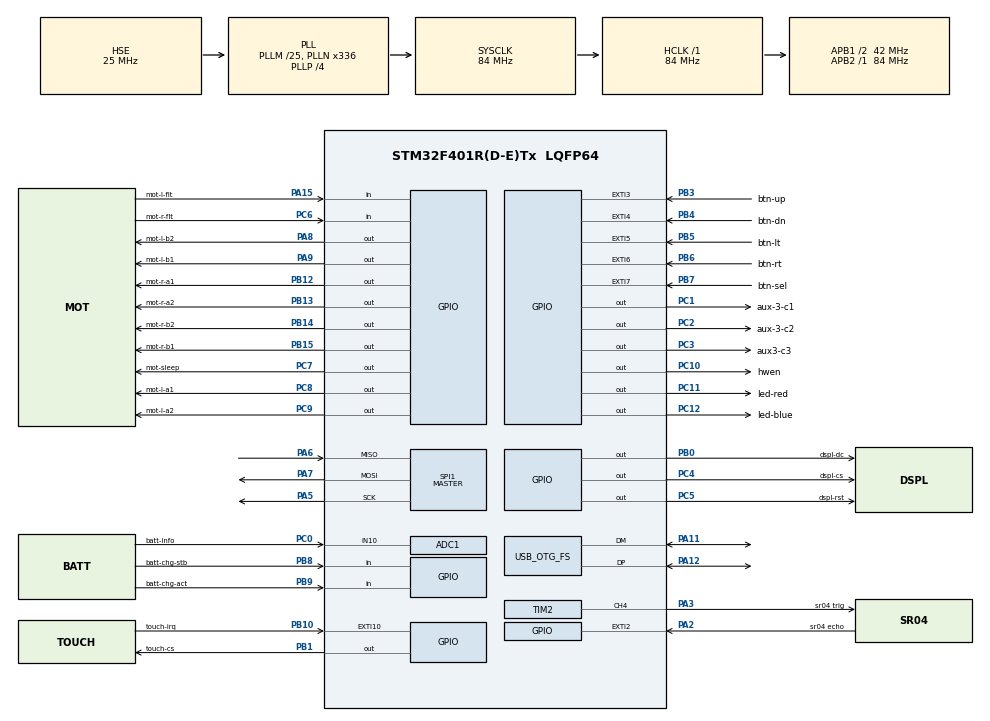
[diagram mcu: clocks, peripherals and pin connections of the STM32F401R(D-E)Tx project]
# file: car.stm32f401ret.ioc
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ADC1.Channel-0\#ChannelRegularConversion=ADC_CHANNEL_10
ADC1.NbrOfConversionFlag=1
ADC1.Rank-0\#ChannelRegularConversion=1
ADC1.SamplingTime-0\#ChannelRegularConversion=ADC_SAMPLETIME_3CYCLES
ADC1.master=1
Dma.Request0=SPI1_TX
Dma.SPI1_TX.0.Direction=DMA_MEMORY_TO_PERIPH
Dma.SPI1_TX.0.FIFOMode=DMA_FIFOMODE_DISABLE
Dma.SPI1_TX.0.Instance=DMA2_Stream3
Dma.SPI1_TX.0.MemDataAlignment=DMA_MDATAALIGN_BYTE
Dma.SPI1_TX.0.MemInc=DMA_MINC_ENABLE
Dma.SPI1_TX.0.Mode=DMA_NORMAL
Dma.SPI1_TX.0.PeriphDataAlignment=DMA_PDATAALIGN_BYTE
Dma.SPI1_TX.0.PeriphInc=DMA_PINC_DISABLE
Dma.SPI1_TX.0.Priority=DMA_PRIORITY_LOW
Mcu.Family=STM32F4
Mcu.Name=STM32F401R(D-E)Tx
Mcu.Package=LQFP64
NVIC.DMA2_Stream3_IRQn=true\:0\:0\:false\:false\:true\:false\:true\:true
NVIC.EXTI2_IRQn=true\:0\:0\:false\:false\:true\:true\:true\:true
NVIC.EXTI3_IRQn=true\:0\:0\:false\:false\:true\:true\:true\:true
NVIC.EXTI4_IRQn=true\:0\:0\:false\:false\:true\:true\:true\:true
NVIC.EXTI9_5_IRQn=true\:0\:0\:false\:false\:true\:true\:true\:true
NVIC.OTG_FS_IRQn=true\:0\:0\:false\:false\:true\:false\:true\:true
NVIC.PriorityGroup=NVIC_PRIORITYGROUP_4
NVIC.TIM1_UP_TIM10_IRQn=true\:0\:0\:false\:false\:true\:true\:true\:true
PA11.Mode=Device_Only
PA11.Signal=USB_OTG_FS_DM
PA12.Mode=Device_Only
PA12.Signal=USB_OTG_FS_DP
PA15.GPIO_Label=mot-l-flt
PA15.GPIO_PuPd=GPIO_PULLUP
PA15.Signal=GPIO_Input
PA2.GPIO_Label=sr04 echo
PA2.GPIO_ModeDefaultEXTI=GPIO_MODE_IT_RISING_FALLING
PA2.GPIO_PuPd=GPIO_PULLDOWN
PA2.Signal=GPXTI2
PA3.GPIO_Label=sr04 trig
PA3.GPIO_Speed=GPIO_SPEED_FREQ_HIGH
PA3.Signal=S_TIM2_CH4
PA5.Mode=Full_Duplex_Master
PA5.Signal=SPI1_SCK
PA6.Mode=Full_Duplex_Master
PA6.Signal=SPI1_MISO
PA7.Mode=Full_Duplex_Master
PA7.Signal=SPI1_MOSI
PA8.GPIO_Label=mot-l-b2
PA8.Signal=GPIO_Output
PA9.GPIO_Label=mot-l-b1
PA9.Signal=GPIO_Output
PB0.GPIO_Label=dspl-dc
PB0.GPIO_Speed=GPIO_SPEED_FREQ_HIGH
PB0.PinState=GPIO_PIN_RESET
PB0.Signal=GPIO_Output
PB1.GPIO_Label=touch-cs
PB1.GPIO_Speed=GPIO_SPEED_FREQ_HIGH
PB1.PinState=GPIO_PIN_SET
PB1.Signal=GPIO_Output
PB10.GPIO_Label=touch-irq
PB10.Signal=GPXTI10
PB12.GPIO_Label=mot-r-a1
PB12.Signal=GPIO_Output
PB13.GPIO_Label=mot-r-a2
PB13.Signal=GPIO_Output
PB14.GPIO_Label=mot-r-b2
PB14.Signal=GPIO_Output
PB15.GPIO_Label=mot-r-b1
PB15.Signal=GPIO_Output
PB3.GPIO_Label=btn-up
PB3.GPIO_ModeDefaultEXTI=GPIO_MODE_IT_FALLING
PB3.GPIO_PuPd=GPIO_PULLUP
PB3.Signal=GPXTI3
PB4.GPIO_Label=btn-dn
PB4.GPIO_ModeDefaultEXTI=GPIO_MODE_IT_FALLING
PB4.GPIO_PuPd=GPIO_PULLUP
PB4.Signal=GPXTI4
PB5.GPIO_Label=btn-lt
PB5.GPIO_ModeDefaultEXTI=GPIO_MODE_IT_FALLING
PB5.GPIO_PuPd=GPIO_PULLUP
PB5.Signal=GPXTI5
PB6.GPIO_Label=btn-rt
PB6.GPIO_ModeDefaultEXTI=GPIO_MODE_IT_FALLING
PB6.GPIO_PuPd=GPIO_PULLUP
PB6.Signal=GPXTI6
PB7.GPIO_Label=btn-sel
PB7.GPIO_ModeDefaultEXTI=GPIO_MODE_IT_FALLING
PB7.GPIO_PuPd=GPIO_PULLUP
PB7.Signal=GPXTI7
PB8.GPIO_Label=batt-chg-stb
PB8.GPIO_PuPd=GPIO_PULLUP
PB8.Signal=GPIO_Input
PB9.GPIO_Label=batt-chg-act
PB9.GPIO_PuPd=GPIO_PULLUP
PB9.Signal=GPIO_Input
PC0.GPIO_Label=batt-info
PC0.Signal=ADCx_IN10
PC1.GPIO_Label=aux-3-c1
PC1.Signal=GPIO_Output
PC10.GPIO_Label=hwen
PC10.PinState=GPIO_PIN_SET
PC10.Signal=GPIO_Output
PC11.GPIO_Label=led-red
PC11.Signal=GPIO_Output
PC12.GPIO_Label=led-blue
PC12.Signal=GPIO_Output
PC14-OSC32_IN.Mode=LSE-External-Oscillator
PC14-OSC32_IN.Signal=RCC_OSC32_IN
PC15-OSC32_OUT.Mode=LSE-External-Oscillator
PC15-OSC32_OUT.Signal=RCC_OSC32_OUT
PC2.GPIO_Label=aux-3-c2
PC2.Signal=GPIO_Output
PC3.GPIO_Label=aux3-c3
PC3.Signal=GPIO_Output
PC4.GPIO_Label=dspl-cs
PC4.GPIO_Speed=GPIO_SPEED_FREQ_HIGH
PC4.PinState=GPIO_PIN_SET
PC4.Signal=GPIO_Output
PC5.GPIO_Label=dspl-rst
PC5.Signal=GPIO_Output
PC6.GPIO_Label=mot-r-flt
PC6.GPIO_PuPd=GPIO_PULLUP
PC6.Signal=GPIO_Input
PC7.GPIO_Label=mot-sleep
PC7.GPIO_Speed=GPIO_SPEED_FREQ_LOW
PC7.PinState=GPIO_PIN_SET
PC7.Signal=GPIO_Output
PC8.GPIO_Label=mot-l-a1
PC8.Signal=GPIO_Output
PC9.GPIO_Label=mot-l-a2
PC9.Signal=GPIO_Output
PH0\ -\ OSC_IN.Mode=HSE-External-Oscillator
PH0\ -\ OSC_IN.Signal=RCC_OSC_IN
PH1\ -\ OSC_OUT.Mode=HSE-External-Oscillator
PH1\ -\ OSC_OUT.Signal=RCC_OSC_OUT
ProjectManager.HeapSize=0x200
ProjectManager.StackSize=0x400
ProjectManager.TargetToolchain=Makefile
RCC.48MHZClocksFreq_Value=48000000
RCC.AHBFreq_Value=84000000
RCC.APB1CLKDivider=RCC_HCLK_DIV2
RCC.APB1Freq_Value=42000000
RCC.APB1TimFreq_Value=84000000
RCC.APB2Freq_Value=84000000
RCC.APB2TimFreq_Value=84000000
RCC.CortexFreq_Value=84000000
RCC.HCLKFreq_Value=84000000
RCC.HSE_VALUE=25000000
RCC.HSI_VALUE=16000000
RCC.PLLM=25
RCC.PLLN=336
RCC.PLLP=RCC_PLLP_DIV4
RCC.PLLQ=7
RCC.RCC_RTC_Clock_Source=RCC_RTCCLKSOURCE_LSE
RCC.RCC_RTC_Clock_SourceVirtual=RCC_RTCCLKSOURCE_LSE
RCC.SYSCLKFreq_VALUE=84000000
RCC.SYSCLKSource=RCC_SYSCLKSOURCE_PLLCLK
RCC.VCOOutputFreq_Value=336000000
SH.ADCx_IN10.0=ADC1_IN10,IN10
SH.S_TIM2_CH4.0=TIM2_CH4,PWM Generation4 CH4
SPI1.BaudRatePrescaler=SPI_BAUDRATEPRESCALER_2
SPI1.Direction=SPI_DIRECTION_2LINES
SPI1.Mode=SPI_MODE_MASTER
SPI1.VirtualType=VM_MASTER
TIM1.AutoReloadPreload=TIM_AUTORELOAD_PRELOAD_DISABLE
TIM1.Period=99
TIM1.Prescaler=839
TIM2.Channel-PWM\ Generation4\ CH4=TIM_CHANNEL_4
TIM2.Period=59999
TIM2.Prescaler=83
TIM2.Pulse-PWM\ Generation4\ CH4=9
USB_DEVICE.CLASS_NAME_FS=CDC
USB_DEVICE.MANUFACTURER_STRING=cliff
USB_DEVICE.PRODUCT_STRING_CDC_FS=car Virtual ComPort
USB_DEVICE.VirtualMode=Cdc
USB_DEVICE.VirtualMode-CDC_FS=Cdc
USB_DEVICE.VirtualModeFS=Cdc_FS
USB_OTG_FS.VirtualMode=Device_Only
VP_RTC_VS_RTC_Activate.Mode=RTC_Enabled
VP_TIM1_VS_ClockSourceINT.Mode=Internal
VP_TIM2_VS_ClockSourceINT.Mode=Internal
VP_USB_DEVICE_VS_USB_DEVICE_CDC_FS.Mode=CDC_FS
board=custom

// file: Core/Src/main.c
/* USER CODE BEGIN Header */
/**
  ******************************************************************************
  * @file           : main.c
  * @brief          : Main program body
  ******************************************************************************
  * @attention
  *
  * Copyright (c) 2025 STMicroelectronics.
  * All rights reserved.
  *
  * This software is licensed under terms that can be found in the LICENSE file
  * in the root directory of this software component.
  * If no LICENSE file comes with this software, it is provided AS-IS.
  *
  ******************************************************************************
  */
/* USER CODE END Header */
#include "main.h"
#include "usb_device.h"

/* USER CODE BEGIN Includes */
#include "../../source/sys/proc.h"

/* USER CODE END Includes */

ADC_HandleTypeDef hadc1;

RTC_HandleTypeDef hrtc;

SPI_HandleTypeDef hspi1;
DMA_HandleTypeDef hdma_spi1_tx;

TIM_HandleTypeDef htim1;
TIM_HandleTypeDef htim2;

void SystemClock_Config(void);
static void MX_GPIO_Init(void);
static void MX_DMA_Init(void);
static void MX_RTC_Init(void);
static void MX_SPI1_Init(void);
static void MX_ADC1_Init(void);
static void MX_TIM1_Init(void);
static void MX_TIM2_Init(void);

int main(void)
{

  /* MCU Configuration--------------------------------------------------------*/

  /* Reset of all peripherals, Initializes the Flash interface and the Systick. */
  HAL_Init();

  /* Configure the system clock */
  SystemClock_Config();

  /* Initialize all configured peripherals */
  MX_GPIO_Init();
  MX_DMA_Init();
  MX_RTC_Init();
  MX_SPI1_Init();
  MX_USB_DEVICE_Init();
  MX_ADC1_Init();
  MX_TIM1_Init();
  MX_TIM2_Init();
  /* USER CODE BEGIN 2 */

    init();

  /* USER CODE END 2 */

  /* Infinite loop */
  /* USER CODE BEGIN WHILE */
  while (1)
  {
    HAL_GPIO_TogglePin(GPIOC, GPIO_PIN_13);
    HAL_Delay(1000);
    /* USER CODE END WHILE */

  }
}

void SystemClock_Config(void)
{
  RCC_OscInitTypeDef RCC_OscInitStruct = {0};
  RCC_ClkInitTypeDef RCC_ClkInitStruct = {0};

  /** Configure the main internal regulator output voltage
  */
  __HAL_RCC_PWR_CLK_ENABLE();
  __HAL_PWR_VOLTAGESCALING_CONFIG(PWR_REGULATOR_VOLTAGE_SCALE2);

  /** Initializes the RCC Oscillators according to the specified parameters
  * in the RCC_OscInitTypeDef structure.
  */
  RCC_OscInitStruct.OscillatorType = RCC_OSCILLATORTYPE_HSE|RCC_OSCILLATORTYPE_LSE;
  RCC_OscInitStruct.HSEState = RCC_HSE_ON;
  RCC_OscInitStruct.LSEState = RCC_LSE_ON;
  RCC_OscInitStruct.PLL.PLLState = RCC_PLL_ON;
  RCC_OscInitStruct.PLL.PLLSource = RCC_PLLSOURCE_HSE;
  RCC_OscInitStruct.PLL.PLLM = 25;
  RCC_OscInitStruct.PLL.PLLN = 336;
  RCC_OscInitStruct.PLL.PLLP = RCC_PLLP_DIV4;
  RCC_OscInitStruct.PLL.PLLQ = 7;
  if (HAL_RCC_OscConfig(&RCC_OscInitStruct) != HAL_OK)
  {
    Error_Handler();
  }

  /** Initializes the CPU, AHB and APB buses clocks
  */
  RCC_ClkInitStruct.ClockType = RCC_CLOCKTYPE_HCLK|RCC_CLOCKTYPE_SYSCLK
                              |RCC_CLOCKTYPE_PCLK1|RCC_CLOCKTYPE_PCLK2;
  RCC_ClkInitStruct.SYSCLKSource = RCC_SYSCLKSOURCE_PLLCLK;
  RCC_ClkInitStruct.AHBCLKDivider = RCC_SYSCLK_DIV1;
  RCC_ClkInitStruct.APB1CLKDivider = RCC_HCLK_DIV2;
  RCC_ClkInitStruct.APB2CLKDivider = RCC_HCLK_DIV1;

  if (HAL_RCC_ClockConfig(&RCC_ClkInitStruct, FLASH_LATENCY_2) != HAL_OK)
  {
    Error_Handler();
  }
}

static void MX_ADC1_Init(void)
{

  ADC_ChannelConfTypeDef sConfig = {0};

  /** Configure the global features of the ADC (Clock, Resolution, Data Alignment and number of conversion)
  */
  hadc1.Instance = ADC1;
  hadc1.Init.ClockPrescaler = ADC_CLOCK_SYNC_PCLK_DIV4;
  hadc1.Init.Resolution = ADC_RESOLUTION_12B;
  hadc1.Init.ScanConvMode = DISABLE;
  hadc1.Init.ContinuousConvMode = DISABLE;
  hadc1.Init.DiscontinuousConvMode = DISABLE;
  hadc1.Init.ExternalTrigConvEdge = ADC_EXTERNALTRIGCONVEDGE_NONE;
  hadc1.Init.ExternalTrigConv = ADC_SOFTWARE_START;
  hadc1.Init.DataAlign = ADC_DATAALIGN_RIGHT;
  hadc1.Init.NbrOfConversion = 1;
  hadc1.Init.DMAContinuousRequests = DISABLE;
  hadc1.Init.EOCSelection = ADC_EOC_SINGLE_CONV;
  if (HAL_ADC_Init(&hadc1) != HAL_OK)
  {
    Error_Handler();
  }

  /** Configure for the selected ADC regular channel its corresponding rank in the sequencer and its sample time.
  */
  sConfig.Channel = ADC_CHANNEL_10;
  sConfig.Rank = 1;
  sConfig.SamplingTime = ADC_SAMPLETIME_3CYCLES;
  if (HAL_ADC_ConfigChannel(&hadc1, &sConfig) != HAL_OK)
  {
    Error_Handler();
  }

}

static void MX_RTC_Init(void)
{

  /** Initialize RTC Only
  */
  hrtc.Instance = RTC;
  hrtc.Init.HourFormat = RTC_HOURFORMAT_24;
  hrtc.Init.AsynchPrediv = 127;
  hrtc.Init.SynchPrediv = 255;
  hrtc.Init.OutPut = RTC_OUTPUT_DISABLE;
  hrtc.Init.OutPutPolarity = RTC_OUTPUT_POLARITY_HIGH;
  hrtc.Init.OutPutType = RTC_OUTPUT_TYPE_OPENDRAIN;
  if (HAL_RTC_Init(&hrtc) != HAL_OK)
  {
    Error_Handler();
  }

}

static void MX_SPI1_Init(void)
{

  /* SPI1 parameter configuration*/
  hspi1.Instance = SPI1;
  hspi1.Init.Mode = SPI_MODE_MASTER;
  hspi1.Init.Direction = SPI_DIRECTION_2LINES;
  hspi1.Init.DataSize = SPI_DATASIZE_8BIT;
  hspi1.Init.CLKPolarity = SPI_POLARITY_LOW;
  hspi1.Init.CLKPhase = SPI_PHASE_1EDGE;
  hspi1.Init.NSS = SPI_NSS_SOFT;
  hspi1.Init.BaudRatePrescaler = SPI_BAUDRATEPRESCALER_2;
  hspi1.Init.FirstBit = SPI_FIRSTBIT_MSB;
  hspi1.Init.TIMode = SPI_TIMODE_DISABLE;
  hspi1.Init.CRCCalculation = SPI_CRCCALCULATION_DISABLE;
  hspi1.Init.CRCPolynomial = 10;
  if (HAL_SPI_Init(&hspi1) != HAL_OK)
  {
    Error_Handler();
  }

}

static void MX_TIM1_Init(void)
{

  TIM_ClockConfigTypeDef sClockSourceConfig = {0};
  TIM_MasterConfigTypeDef sMasterConfig = {0};

  htim1.Instance = TIM1;
  htim1.Init.Prescaler = 839;
  htim1.Init.CounterMode = TIM_COUNTERMODE_UP;
  htim1.Init.Period = 99;
  htim1.Init.ClockDivision = TIM_CLOCKDIVISION_DIV1;
  htim1.Init.RepetitionCounter = 0;
  htim1.Init.AutoReloadPreload = TIM_AUTORELOAD_PRELOAD_DISABLE;
  if (HAL_TIM_Base_Init(&htim1) != HAL_OK)
  {
    Error_Handler();
  }
  sClockSourceConfig.ClockSource = TIM_CLOCKSOURCE_INTERNAL;
  if (HAL_TIM_ConfigClockSource(&htim1, &sClockSourceConfig) != HAL_OK)
  {
    Error_Handler();
  }
  sMasterConfig.MasterOutputTrigger = TIM_TRGO_RESET;
  sMasterConfig.MasterSlaveMode = TIM_MASTERSLAVEMODE_DISABLE;
  if (HAL_TIMEx_MasterConfigSynchronization(&htim1, &sMasterConfig) != HAL_OK)
  {
    Error_Handler();
  }

}

static void MX_TIM2_Init(void)
{

  TIM_ClockConfigTypeDef sClockSourceConfig = {0};
  TIM_MasterConfigTypeDef sMasterConfig = {0};
  TIM_OC_InitTypeDef sConfigOC = {0};

  htim2.Instance = TIM2;
  htim2.Init.Prescaler = 83;
  htim2.Init.CounterMode = TIM_COUNTERMODE_UP;
  htim2.Init.Period = 59999;
  htim2.Init.ClockDivision = TIM_CLOCKDIVISION_DIV1;
  htim2.Init.AutoReloadPreload = TIM_AUTORELOAD_PRELOAD_DISABLE;
  if (HAL_TIM_Base_Init(&htim2) != HAL_OK)
  {
    Error_Handler();
  }
  sClockSourceConfig.ClockSource = TIM_CLOCKSOURCE_INTERNAL;
  if (HAL_TIM_ConfigClockSource(&htim2, &sClockSourceConfig) != HAL_OK)
  {
    Error_Handler();
  }
  if (HAL_TIM_PWM_Init(&htim2) != HAL_OK)
  {
    Error_Handler();
  }
  sMasterConfig.MasterOutputTrigger = TIM_TRGO_RESET;
  sMasterConfig.MasterSlaveMode = TIM_MASTERSLAVEMODE_DISABLE;
  if (HAL_TIMEx_MasterConfigSynchronization(&htim2, &sMasterConfig) != HAL_OK)
  {
    Error_Handler();
  }
  sConfigOC.OCMode = TIM_OCMODE_PWM1;
  sConfigOC.Pulse = 9;
  sConfigOC.OCPolarity = TIM_OCPOLARITY_HIGH;
  sConfigOC.OCFastMode = TIM_OCFAST_DISABLE;
  if (HAL_TIM_PWM_ConfigChannel(&htim2, &sConfigOC, TIM_CHANNEL_4) != HAL_OK)
  {
    Error_Handler();
  }
  HAL_TIM_MspPostInit(&htim2);

}

static void MX_DMA_Init(void)
{

  /* DMA controller clock enable */
  __HAL_RCC_DMA2_CLK_ENABLE();

  /* DMA interrupt init */
  /* DMA2_Stream3_IRQn interrupt configuration */
  HAL_NVIC_SetPriority(DMA2_Stream3_IRQn, 0, 0);
  HAL_NVIC_EnableIRQ(DMA2_Stream3_IRQn);

}

static void MX_GPIO_Init(void)
{
  GPIO_InitTypeDef GPIO_InitStruct = {0};

  /* GPIO Ports Clock Enable */
  __HAL_RCC_GPIOC_CLK_ENABLE();
  __HAL_RCC_GPIOH_CLK_ENABLE();
  __HAL_RCC_GPIOA_CLK_ENABLE();
  __HAL_RCC_GPIOB_CLK_ENABLE();

  /*Configure GPIO pin Output Level */
  HAL_GPIO_WritePin(GPIOC, aux_3_c1_Pin|aux_3_c2_Pin|aux3_c3_Pin|dspl_rst_Pin
                          |mot_l_a1_Pin|mot_l_a2_Pin|led_red_Pin|led_blue_Pin, GPIO_PIN_RESET);

  /*Configure GPIO pin Output Level */
  HAL_GPIO_WritePin(GPIOC, dspl_cs_Pin|mot_sleep_Pin|hwen_Pin, GPIO_PIN_SET);

  /*Configure GPIO pin Output Level */
  HAL_GPIO_WritePin(GPIOB, dspl_dc_Pin|mot_r_a1_Pin|mot_r_a2_Pin|mot_r_b2_Pin
                          |mot_r_b1_Pin, GPIO_PIN_RESET);

  /*Configure GPIO pin Output Level */
  HAL_GPIO_WritePin(touch_cs_GPIO_Port, touch_cs_Pin, GPIO_PIN_SET);

  /*Configure GPIO pin Output Level */
  HAL_GPIO_WritePin(GPIOA, mot_l_b2_Pin|mot_l_b1_Pin, GPIO_PIN_RESET);

  /*Configure GPIO pins : aux_3_c1_Pin aux_3_c2_Pin aux3_c3_Pin dspl_rst_Pin
                           mot_sleep_Pin mot_l_a1_Pin mot_l_a2_Pin hwen_Pin
                           led_red_Pin led_blue_Pin */
  GPIO_InitStruct.Pin = aux_3_c1_Pin|aux_3_c2_Pin|aux3_c3_Pin|dspl_rst_Pin
                          |mot_sleep_Pin|mot_l_a1_Pin|mot_l_a2_Pin|hwen_Pin
                          |led_red_Pin|led_blue_Pin;
  GPIO_InitStruct.Mode = GPIO_MODE_OUTPUT_PP;
  GPIO_InitStruct.Pull = GPIO_NOPULL;
  GPIO_InitStruct.Speed = GPIO_SPEED_FREQ_LOW;
  HAL_GPIO_Init(GPIOC, &GPIO_InitStruct);

  /*Configure GPIO pin : sr04_echo_Pin */
  GPIO_InitStruct.Pin = sr04_echo_Pin;
  GPIO_InitStruct.Mode = GPIO_MODE_IT_RISING_FALLING;
  GPIO_InitStruct.Pull = GPIO_PULLDOWN;
  HAL_GPIO_Init(sr04_echo_GPIO_Port, &GPIO_InitStruct);

  /*Configure GPIO pin : dspl_cs_Pin */
  GPIO_InitStruct.Pin = dspl_cs_Pin;
  GPIO_InitStruct.Mode = GPIO_MODE_OUTPUT_PP;
  GPIO_InitStruct.Pull = GPIO_NOPULL;
  GPIO_InitStruct.Speed = GPIO_SPEED_FREQ_HIGH;
  HAL_GPIO_Init(dspl_cs_GPIO_Port, &GPIO_InitStruct);

  /*Configure GPIO pins : dspl_dc_Pin touch_cs_Pin */
  GPIO_InitStruct.Pin = dspl_dc_Pin|touch_cs_Pin;
  GPIO_InitStruct.Mode = GPIO_MODE_OUTPUT_PP;
  GPIO_InitStruct.Pull = GPIO_NOPULL;
  GPIO_InitStruct.Speed = GPIO_SPEED_FREQ_HIGH;
  HAL_GPIO_Init(GPIOB, &GPIO_InitStruct);

  /*Configure GPIO pin : touch_irq_Pin */
  GPIO_InitStruct.Pin = touch_irq_Pin;
  GPIO_InitStruct.Mode = GPIO_MODE_IT_RISING;
  GPIO_InitStruct.Pull = GPIO_NOPULL;
  HAL_GPIO_Init(touch_irq_GPIO_Port, &GPIO_InitStruct);

  /*Configure GPIO pins : mot_r_a1_Pin mot_r_a2_Pin mot_r_b2_Pin mot_r_b1_Pin */
  GPIO_InitStruct.Pin = mot_r_a1_Pin|mot_r_a2_Pin|mot_r_b2_Pin|mot_r_b1_Pin;
  GPIO_InitStruct.Mode = GPIO_MODE_OUTPUT_PP;
  GPIO_InitStruct.Pull = GPIO_NOPULL;
  GPIO_InitStruct.Speed = GPIO_SPEED_FREQ_LOW;
  HAL_GPIO_Init(GPIOB, &GPIO_InitStruct);

  /*Configure GPIO pin : mot_r_flt_Pin */
  GPIO_InitStruct.Pin = mot_r_flt_Pin;
  GPIO_InitStruct.Mode = GPIO_MODE_INPUT;
  GPIO_InitStruct.Pull = GPIO_PULLUP;
  HAL_GPIO_Init(mot_r_flt_GPIO_Port, &GPIO_InitStruct);

  /*Configure GPIO pins : mot_l_b2_Pin mot_l_b1_Pin */
  GPIO_InitStruct.Pin = mot_l_b2_Pin|mot_l_b1_Pin;
  GPIO_InitStruct.Mode = GPIO_MODE_OUTPUT_PP;
  GPIO_InitStruct.Pull = GPIO_NOPULL;
  GPIO_InitStruct.Speed = GPIO_SPEED_FREQ_LOW;
  HAL_GPIO_Init(GPIOA, &GPIO_InitStruct);

  /*Configure GPIO pin : mot_l_flt_Pin */
  GPIO_InitStruct.Pin = mot_l_flt_Pin;
  GPIO_InitStruct.Mode = GPIO_MODE_INPUT;
  GPIO_InitStruct.Pull = GPIO_PULLUP;
  HAL_GPIO_Init(mot_l_flt_GPIO_Port, &GPIO_InitStruct);

  /*Configure GPIO pins : btn_up_Pin btn_dn_Pin btn_lt_Pin btn_rt_Pin
                           btn_sel_Pin */
  GPIO_InitStruct.Pin = btn_up_Pin|btn_dn_Pin|btn_lt_Pin|btn_rt_Pin
                          |btn_sel_Pin;
  GPIO_InitStruct.Mode = GPIO_MODE_IT_FALLING;
  GPIO_InitStruct.Pull = GPIO_PULLUP;
  HAL_GPIO_Init(GPIOB, &GPIO_InitStruct);

  /*Configure GPIO pins : batt_chg_stb_Pin batt_chg_act_Pin */
  GPIO_InitStruct.Pin = batt_chg_stb_Pin|batt_chg_act_Pin;
  GPIO_InitStruct.Mode = GPIO_MODE_INPUT;
  GPIO_InitStruct.Pull = GPIO_PULLUP;
  HAL_GPIO_Init(GPIOB, &GPIO_InitStruct);

  /* EXTI interrupt init*/
  HAL_NVIC_SetPriority(EXTI2_IRQn, 0, 0);
  HAL_NVIC_EnableIRQ(EXTI2_IRQn);

  HAL_NVIC_SetPriority(EXTI3_IRQn, 0, 0);
  HAL_NVIC_EnableIRQ(EXTI3_IRQn);

  HAL_NVIC_SetPriority(EXTI4_IRQn, 0, 0);
  HAL_NVIC_EnableIRQ(EXTI4_IRQn);

  HAL_NVIC_SetPriority(EXTI9_5_IRQn, 0, 0);
  HAL_NVIC_EnableIRQ(EXTI9_5_IRQn);

}

void Error_Handler(void)
{
  __disable_irq();
  while (1)
  {
  }
}
